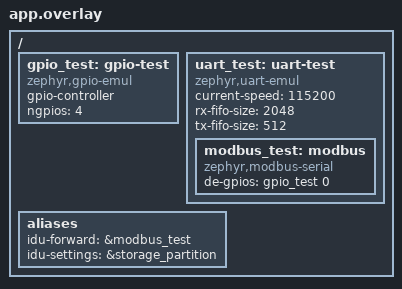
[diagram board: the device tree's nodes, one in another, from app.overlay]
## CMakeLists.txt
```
cmake_minimum_required(VERSION 3.20.0)
get_filename_component(IDU_APP ${CMAKE_CURRENT_SOURCE_DIR}/../.. ABSOLUTE)
include(${IDU_APP}/modules/modules.cmake)
find_package(Zephyr REQUIRED HINTS $ENV{ZEPHYR_BASE})
project(idu_shared_rs485_tests)
target_include_directories(app PRIVATE ${IDU_APP}/app)
target_sources(app PRIVATE src/main.c ${IDU_APP}/app/protocol/ports.c
  ${IDU_APP}/app/protocol/init.c ${IDU_APP}/app/protocol/tasks.c)
add_subdirectory(${IDU_APP}/app/protocol app_cfg)
add_subdirectory(${IDU_APP}/app/process point_process)
```

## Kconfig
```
mainmenu "Product shared RS485 tests"
config MODBUS_BUFFER_SIZE
    range 64 1100
source "Kconfig.zephyr"
rsource "../../app/Kconfig"
```

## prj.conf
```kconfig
CONFIG_ZTEST=y
CONFIG_MODBUS=y
CONFIG_MODBUS_BUFFER_SIZE=1100
CONFIG_MODBUS_ROLE_CLIENT_SERVER=y
CONFIG_MODBUS_FP_EXTENSIONS=n
CONFIG_MODBUS_RAW_ADU=y
CONFIG_DATAPROCESS=y
CONFIG_DP_PARAMS=y
CONFIG_ZBUS_PREFER_DYNAMIC_ALLOCATION=n
CONFIG_ZBUS_MSG_SUBSCRIBER_BUF_ALLOC_STATIC=y
CONFIG_ZBUS_MSG_SUBSCRIBER_NET_BUF_POOL_SIZE=2
CONFIG_ZBUS_MSG_SUBSCRIBER_NET_BUF_STATIC_DATA_SIZE=640
CONFIG_MAIN_STACK_SIZE=4096
CONFIG_TEST_EXTRA_STACK_SIZE=4096
CONFIG_SYSTEM_WORKQUEUE_STACK_SIZE=2048
CONFIG_NATIVE_SIM_SLOWDOWN_TO_REAL_TIME=n
CONFIG_FLASH=y
CONFIG_FLASH_MAP=y
CONFIG_FLASH_PAGE_LAYOUT=y
CONFIG_FLASH_SIMULATOR_CALLBACKS=y
CONFIG_GPIO=y
CONFIG_SERIAL=y
CONFIG_EMUL=y
CONFIG_UART_EMUL=y
CONFIG_UART_INTERRUPT_DRIVEN=y
CONFIG_UART_USE_RUNTIME_CONFIGURE=y
CONFIG_MODBUS_NONCOMPLIANT_SERIAL_MODE=y
CONFIG_CO_MODBUS_ADAPTER=y
CONFIG_CO_MODBUS_RAW_PORT=y
CONFIG_TR_MODBUS_ADAPTER=y
CONFIG_TR_MODBUS_RAW_PORT=y
CONFIG_MODBUS_NUMOF_RAW_ADU=2
CONFIG_VPORT_MAX_PORTS=2
CONFIG_CO_MAX_BUSES=1
CONFIG_TR_PORTS=1
```

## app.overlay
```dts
#include <zephyr/dt-bindings/gpio/gpio.h>
/ {
    gpio_test: gpio-test {
        compatible = "zephyr,gpio-emul";
        gpio-controller;
        #gpio-cells = <2>;
        ngpios = <4>;
        status = "okay";
    };
    uart_test: uart-test {
        compatible = "zephyr,uart-emul";
        current-speed = <115200>;
        rx-fifo-size = <2048>;
        tx-fifo-size = <512>;
        status = "okay";
        modbus_test: modbus {
            compatible = "zephyr,modbus-serial";
            de-gpios = <&gpio_test 0 GPIO_ACTIVE_HIGH>;
            status = "okay";
        };
    };
};
/ { aliases { idu-forward = &modbus_test; idu-settings = &storage_partition; }; };
```

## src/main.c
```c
#include "protocol/inc/protocol.h"
#include "protocol/inc/signal_ids.h"
#include <collect/collect.h>
#include <collect/port.h>
#include <dataprocess/params.h>
#include <dataprocess/process.h>
#include <transmit/forward.h>
#include <zephyr/drivers/serial/uart_emul.h>
#include <zephyr/drivers/gpio/gpio_emul.h>
#include <zephyr/storage/flash_map.h>
#include <zephyr/sys/byteorder.h>
#include <zephyr/sys/crc.h>
#include <zephyr/ztest.h>
#include <errno.h>
#include <string.h>

BUILD_ASSERT(!IS_ENABLED(CONFIG_CO_SIMULATOR));
DEVICE_DT_DEFINE(DT_NODELABEL(modbus_test), NULL, NULL, NULL, NULL, POST_KERNEL, 90, NULL);
static const struct device *uart = DEVICE_DT_GET(DT_NODELABEL(uart_test));
static const struct gpio_dt_spec de = GPIO_DT_SPEC_GET(DT_NODELABEL(modbus_test), de_gpios);
static uint8_t outgoing[CONFIG_MODBUS_BUFFER_SIZE], reply[CONFIG_MODBUS_BUFFER_SIZE];
static uint8_t slave_reply[CONFIG_MODBUS_BUFFER_SIZE];
static size_t outgoing_size, reply_size, slave_size;
static atomic_t requests, writes, fault;
static uint16_t setpoint = 100;
static uint16_t second_setpoint = 100;
static K_SEM_DEFINE(north_done, 0, 1);
static K_SEM_DEFINE(north_sending, 0, 1);
static K_SEM_DEFINE(north_release, 0, 1);
static bool hold_north_send;
static struct k_work_delayable respond;

typedef enum { NORMAL, NO_REPLY, WRONG_UNIT, WRONG_FUNCTION, WRONG_LENGTH, BAD_CRC, EXCEPTION, NORTH_REQUEST } response_scenario_t;

/* 外部从机夹具通过 UART 注入完整帧，不链接产品内置模拟后端。 */
static void respond_work(struct k_work *work)
{
    ARG_UNUSED(work);
    zassert_equal(uart_emul_put_rx_data(uart, slave_reply, slave_size), slave_size);
}
static void transmitted(const struct device *dev, size_t bytes, void *user)
{
    ARG_UNUSED(bytes); ARG_UNUSED(user);
    outgoing_size += uart_emul_get_tx_data(dev, outgoing + outgoing_size,
                                           sizeof(outgoing) - outgoing_size);
    if (outgoing_size < 3) { return; }
    bool south = outgoing[0] == 1 || outgoing[0] == 2;
    size_t length = south ? (outgoing[1] == 16 ? (outgoing_size < 7 ? 0 : 9U + outgoing[6]) : 8) :
        ((outgoing[1] == 3 || outgoing[1] == 4) ? 5U + outgoing[2] : (outgoing[1] & 0x80) ? 5 : 8);
    if (!length || outgoing_size < length) { return; }
    zassert_equal(outgoing_size, length);
    zassert_equal(crc16_ansi(outgoing, length - 2), sys_get_le16(outgoing + length - 2));
    if (!south) {
        memcpy(reply, outgoing, length); reply_size = length; outgoing_size = 0;
        if (hold_north_send) {
            k_sem_give(&north_sending);
            zassert_ok(k_sem_take(&north_release, K_SECONDS(1)));
        }
        k_sem_give(&north_done); return;
    }
    atomic_inc(&requests);
    slave_reply[0] = outgoing[0]; slave_reply[1] = outgoing[1];
    uint16_t *target = outgoing[0] == 1 ? &setpoint : &second_setpoint;
    uint16_t address = sys_get_be16(outgoing + 2);
    if (outgoing[1] == 3 || outgoing[1] == 4) {
        uint16_t count = sys_get_be16(outgoing + 4);
        slave_size = 5 + 2 * count; slave_reply[2] = 2 * count;
        for (size_t i = 0; i < count; ++i) {
            uint16_t value = address == 40000 ? *target : outgoing[0] == 1 ? 0x55aa : 0x33cc;
            if (address + i == 30459) { value = outgoing[0]; }
            if (address + i == 8150) { value = 0x0101; }
            if (address + i == 8151) { value = 0x0100; }
            sys_put_be16(value, slave_reply + 3 + i * 2);
        }
    } else {
        *target = sys_get_be16(outgoing + (outgoing[1] == 6 ? 4 : 7));
        atomic_inc(&writes);
        memcpy(slave_reply + 2, outgoing + 2, 4); slave_size = 8;
    }
    outgoing_size = 0;
    switch (atomic_get(&fault)) {
    case NO_REPLY: return;
    case WRONG_UNIT: slave_reply[0] = 20; break;
    case WRONG_FUNCTION: slave_reply[1] = 7; break;
    case WRONG_LENGTH: slave_reply[2] += 2; break;
    case EXCEPTION: slave_reply[1] |= 0x80; slave_reply[2] = MODBUS_EXC_ILLEGAL_DATA_ADDR; slave_size = 5; break;
    case NORTH_REQUEST:
        slave_reply[0] = 16; slave_reply[1] = 3;
        sys_put_be16(31000, slave_reply + 2); sys_put_be16(1, slave_reply + 4);
        slave_size = 8; break;
    default: break;
    }
    sys_put_le16(crc16_ansi(slave_reply, slave_size - 2) ^ (atomic_get(&fault) == BAD_CRC),
                 slave_reply + slave_size - 2);
    k_work_reschedule(&respond, K_MSEC(3));
}
static void request(uint8_t fc, uint16_t address, uint16_t count_or_value)
{
    /* 模拟主站留出总线静默时间，然后发起一次完整请求。 */
    k_msleep(5); k_sem_reset(&north_done);
    uint8_t data[] = {16, fc, 0, 0, 0, 0, 0, 0};
    sys_put_be16(address, data + 2); sys_put_be16(count_or_value, data + 4);
    sys_put_le16(crc16_ansi(data, 6), data + 6);
    zassert_equal(uart_emul_put_rx_data(uart, data, sizeof(data)), sizeof(data));
    zassert_ok(k_sem_take(&north_done, K_MSEC(1500)));
    k_msleep(5);
    zassert_equal(reply[0], 16);
    zassert_equal(gpio_emul_output_get(de.port, de.pin), 0);
}
static void local_address(uint16_t address)
{
    zassert_ok(dp_set_sig_value(DEVICE_LOCAL, SIGNAL_ADDRESS, sizeof(address), (uint8_t *)&address));
}
static void *setup(void)
{
    k_work_init_delayable(&respond, respond_work);
    uart_emul_callback_tx_data_ready_set(uart, transmitted, NULL);
    /* 本套件不测试跨进程恢复，每次从空存储开始，避免复用旧固件的 schema。 */
    const struct flash_area *area;
    zassert_ok(flash_area_open(DT_FIXED_PARTITION_ID(DT_ALIAS(idu_settings)), &area));
    zassert_ok(flash_area_erase(area, 0, area->fa_size));
    flash_area_close(area);
    zassert_ok(protocol_init());
    /* 真实产品任务发现两个远端；随后只禁用周期请求，
     * 让专门的线路断言从安静状态开始。 */
    for (int attempt = 0; attempt < 200; ++attempt) {
        struct co_device_status first, second;
        zassert_ok(co_device_status(DEVICE_REMOTE_IO, &first));
        zassert_ok(co_device_status(DEVICE_REMOTE_IO + 1, &second));
        if (first.state == CO_DEVICE_ONLINE && second.state == CO_DEVICE_ONLINE) { break; }
        zassert_true(attempt < 199, "discovery: %d/%d errors %d/%d",
                     first.state, second.state, first.error, second.error);
        k_msleep(10);
    }
    for (size_t i = 0; i < dp_config()->collect_count; ++i) {
        zassert_ok(co_enable_poll(i, false));
    }
    /* 等待任务已选中的事务完成。 */
    zassert_ok(co_set_port_mode(0, MODE_TRAN, 500));
    zassert_ok(co_set_mode(0, CO_PORT_POLL));
    zassert_ok(protocol_error());
    local_address(16);
    return NULL;
}
ZTEST(shared_rs485, test_collection_and_cached_north_read)
{
    zassert_ok(co_poll(0));
    struct dp_point_state state;
    for (int i = 0; i < 100; ++i) {
        zassert_ok(dp_read((struct dp_key){DEVICE_REMOTE_IO, SIGNAL_DI}, &state));
        if (state.quality == DP_QUALITY_GOOD) { break; }
        k_msleep(1);
    }
    zassert_equal(state.quality, DP_QUALITY_GOOD);
    zassert_equal(state.value.words[0], 0x55aa);
    int before = atomic_get(&requests);
    request(4, 10000, 1);
    zassert_equal(reply[1], 4); zassert_equal(reply_size, 7);
    zassert_equal(sys_get_be16(reply + 3), 0x55aa);
    zassert_equal(atomic_get(&requests), before);
}
ZTEST(shared_rs485, test_two_devices_share_tables_but_keep_independent_values)
{
    zassert_equal(protocol_device_count(), 3);
    zassert_equal(dp_config()->device_count, 2);
    for (size_t i = 0; i < dp_config()->collect_count; ++i) {
        struct co_cfg scratch;
        const struct co_cfg *poll = dp_config_collect(dp_config(), i, &scratch);
        if (poll->fields[0].sig_id == SIGNAL_DI) { zassert_ok(co_poll(i)); }
    }
    struct dp_point_state first, second;
    for (int i = 0; i < 100; ++i) {
        zassert_ok(dp_read((struct dp_key){10, SIGNAL_DI}, &first));
        zassert_ok(dp_read((struct dp_key){11, SIGNAL_DI}, &second));
        if (first.quality == DP_QUALITY_GOOD && second.quality == DP_QUALITY_GOOD) { break; }
        k_msleep(1);
    }
    zassert_equal(first.quality, DP_QUALITY_GOOD);
    zassert_equal(second.quality, DP_QUALITY_GOOD);
    zassert_equal(first.value.words[0], 0x55aa);
    zassert_equal(second.value.words[0], 0x33cc);
}
ZTEST(shared_rs485, test_north_write_waits_for_south_reply_on_same_uart)
{
    int before = atomic_get(&writes);
    request(6, 31500, 321);
    zassert_equal(reply[1], 6); zassert_equal(reply_size, 8);
    zassert_equal(sys_get_be16(reply + 2), 31500);
    zassert_equal(sys_get_be16(reply + 4), 321);
    zassert_equal(setpoint, 321);
    zassert_equal(atomic_get(&writes), before + 1);
}
ZTEST(shared_rs485, test_timeouts_malformed_and_exception_responses_release_bus)
{
    uint16_t value;
    for (int f = NO_REPLY; f <= EXCEPTION; ++f) {
        atomic_set(&fault, f);
        int err = co_read(DEVICE_REMOTE_IO, 4, 8152, &value, 1);
        zassert_equal(err, f == EXCEPTION ? MODBUS_EXC_ILLEGAL_DATA_ADDR : -ETIMEDOUT, "fault=%d err=%d", f, err);
        atomic_set(&fault, NORMAL);
        zassert_ok(co_read(DEVICE_REMOTE_IO, 4, 8152, &value, 1));
        zassert_equal(value, 0x55aa);
        request(3, 31000, 1); zassert_equal(reply[1], 3);
    }
}
ZTEST(shared_rs485, test_gpio_address_does_not_change_initialized_station)
{
    local_address(1);
    uint16_t value;
    zassert_ok(co_read(DEVICE_REMOTE_IO, 4, 8152, &value, 1));
    request(3, 31000, 1);
    zassert_equal(reply[0], 16);
    local_address(16);
    zassert_ok(co_read(DEVICE_REMOTE_IO, 4, 8152, &value, 1));
}
ZTEST(shared_rs485, test_north_request_during_collection_is_not_a_slave_response)
{
    uint16_t value;
    k_sem_reset(&north_done); atomic_set(&fault, NORTH_REQUEST);
    zassert_equal(co_read(DEVICE_REMOTE_IO, 4, 8152, &value, 1), -ETIMEDOUT);
    zassert_equal(k_sem_count_get(&north_done), 0);
    atomic_set(&fault, NORMAL);
    request(3, 31000, 1); zassert_equal(reply[1], 3);
}
ZTEST(shared_rs485, test_z_periodic_worker_updates_cache_on_the_shared_wire)
{
    struct co_device_status before, after;
    struct co_device_status second_before, second_after;
    zassert_ok(co_device_status(DEVICE_REMOTE_IO, &before));
    zassert_ok(co_device_status(DEVICE_REMOTE_IO + 1, &second_before));
    for (size_t i = 0; i < dp_config()->collect_count; ++i) {
        zassert_ok(co_enable_poll(i, true));
    }
    k_msleep(1200);
    /* 禁用周期通信前，等待活动轮询完成。 */
    zassert_ok(co_set_port_mode(0, MODE_TRAN, 500));
    zassert_ok(co_device_status(DEVICE_REMOTE_IO, &after));
    zassert_ok(co_device_status(DEVICE_REMOTE_IO + 1, &second_after));
    /* 每台三个周期测点，两个设备都应完成多于一轮；不能用全局采集项数比较单台统计。 */
    zassert_true(after.successes > before.successes + 3);
    zassert_true(second_after.successes > second_before.successes + 3);
    int count = atomic_get(&requests);
    request(4, 10000, 1); zassert_equal(reply[1], 4);
    zassert_equal(atomic_get(&requests), count);
}
ZTEST(shared_rs485, test_total_budget_includes_northbound_wire_contention)
{
    struct co_device_status before, after;
    zassert_ok(co_device_status(DEVICE_REMOTE_IO, &before));
    int sent = atomic_get(&requests);
    hold_north_send = true;
    k_sem_reset(&north_done);
    uint8_t data[] = {16, 3, 0x79, 0x18, 0, 1, 0, 0}; /* 缓存值为 31000。 */
    sys_put_le16(crc16_ansi(data, 6), data + 6);
    zassert_equal(uart_emul_put_rx_data(uart, data, sizeof(data)), sizeof(data));
    zassert_ok(k_sem_take(&north_sending, K_SECONDS(1)));
    uint16_t value;
    int64_t start = k_uptime_get();
    int err = co_read(DEVICE_REMOTE_IO, 4, 8152, &value, 1);
    int64_t elapsed = k_uptime_get() - start;
    hold_north_send = false;
    k_sem_give(&north_release);
    zassert_ok(k_sem_take(&north_done, K_SECONDS(1)));
    k_msleep(20);
    zassert_equal(err, -EBUSY);
    zassert_between_inclusive(elapsed, 490, 520);
    zassert_equal(atomic_get(&requests), sent);
    zassert_ok(co_device_status(DEVICE_REMOTE_IO, &after));
    /* failures 统计所有失败调用，包括本地竞争；
     * 错误分类必须与远端存活状态分开。 */
    zassert_equal(after.error, -EBUSY);
    zassert_equal(after.state, before.state);
    zassert_equal(after.online, before.online);
    zassert_equal(after.last_response, before.last_response);
    zassert_ok(co_read(DEVICE_REMOTE_IO, 4, 8152, &value, 1));
    request(3, 31000, 1);
}
ZTEST(shared_rs485, test_zz_terminal_stop_rejects_new_business)
{
    protocol_stop();
    protocol_stop(); /* 生命周期只启动了一部分时，重复调用也应幂等。 */
    uint16_t value;
    struct dp_point_state state;
    zassert_equal(co_read(DEVICE_REMOTE_IO, 4, 8152, &value, 1), -ECANCELED);
    zassert_equal(dp_read((struct dp_key){DEVICE_REMOTE_IO, SIGNAL_DI}, &state), -ECANCELED);
    zassert_equal(dp_submit_sig_value((struct dp_key){DEVICE_LOCAL, SIGNAL_DI},
                                     &value, 1, K_MSEC(20), NULL), -ECANCELED);
    k_msleep(20);
    int sent = atomic_get(&requests);
    uint8_t data[] = {16, 6, 0x7b, 0x0c, 0, 42, 0, 0}; /* 31500 */
    sys_put_le16(crc16_ansi(data, 6), data + 6);
    k_sem_reset(&north_done);
    zassert_equal(uart_emul_put_rx_data(uart, data, sizeof(data)), sizeof(data));
    zassert_equal(k_sem_take(&north_done, K_MSEC(200)), -EAGAIN);
    zassert_equal(atomic_get(&requests), sent);
    zassert_equal(protocol_init(), -ECANCELED);
    zassert_equal(dp_set_para_not_dm(NULL, NULL), -ECANCELED);
    zassert_equal(co_dp_fast_set(NULL, NULL), -ECANCELED);
    zassert_equal(co_anlysis_mb_pkg(DEVICE_REMOTE_IO, 0, NULL, 0), -ECANCELED);
    zassert_equal(co_reconfigure(0, (struct modbus_iface_param){0}), -ECANCELED);
}
ZTEST_SUITE(shared_rs485, NULL, setup, NULL, NULL, NULL);
```
